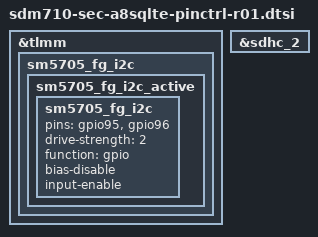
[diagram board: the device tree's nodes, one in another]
/* Copyright (c) 2016-2017, The Linux Foundation. All rights reserved.
 *
 * This program is free software; you can redistribute it and/or modify
 * it under the terms of the GNU General Public License version 2 and
 * only version 2 as published by the Free Software Foundation.
 *
 * This program is distributed in the hope that it will be useful,
 * but WITHOUT ANY WARRANTY; without even the implied warranty of
 * MERCHANTABILITY or FITNESS FOR A PARTICULAR PURPOSE.  See the
 * GNU General Public License for more details.
 */

#include "sdm710-sec-a8sqlte-pinctrl-r00.dtsi"

&tlmm {
	sm5705_fg_i2c {
		sm5705_fg_i2c_active: sm5705_fg_i2c_active {
			sm5705_fg_i2c {
				pins = "gpio95", "gpio96";
				drive-strength = <2>;
				function = "gpio";
				bias-disable;
				input-enable;
			};
		};
	};
	/delete-node/cd_on;
	/delete-node/cd_off;
};

&sdhc_2 {
	/delete-property/pinctrl-0;
	/delete-property/pinctrl-1;
};
